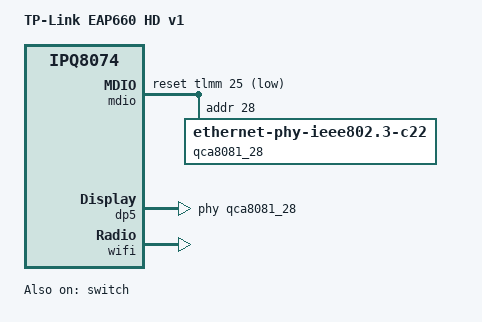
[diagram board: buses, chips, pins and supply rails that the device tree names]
// SPDX-License-Identifier: GPL-2.0-or-later OR MIT

/dts-v1/;

#include "ipq8072-tplink.dtsi"

/ {
	model = "TP-Link EAP660 HD v1";
	compatible = "tplink,eap660hd-v1", "qcom,ipq8074";
};

&mdio {
	status = "okay";

	pinctrl-0 = <&mdio_pins>;
	pinctrl-names = "default";
	reset-gpios = <&tlmm 25 GPIO_ACTIVE_LOW>;

	qca8081_28: ethernet-phy@28 {
		compatible = "ethernet-phy-ieee802.3-c22";
		reg = <28>;
	};
};

&dp5 {
	status = "okay";
	phy-handle = <&qca8081_28>;
	label = "lan";
};

&switch {
	status = "okay";
	switch_lan_bmp = <ESS_PORT5>;
	switch_mac_mode1 = <MAC_MODE_SGMII_PLUS>;

	qcom,port_phyinfo {
		port@5 {
			phy_address = <28>;
			port_id = <5>;
			port_mac_sel = "QGMAC_PORT";
		};
	};
};

&wifi {
	status = "okay";
	qcom,ath11k-fw-memory-mode = <1>;
	qcom,ath11k-calibration-variant = "TP-Link-EAP660-HD-v1";
};

&edma {
	status = "okay";
};
